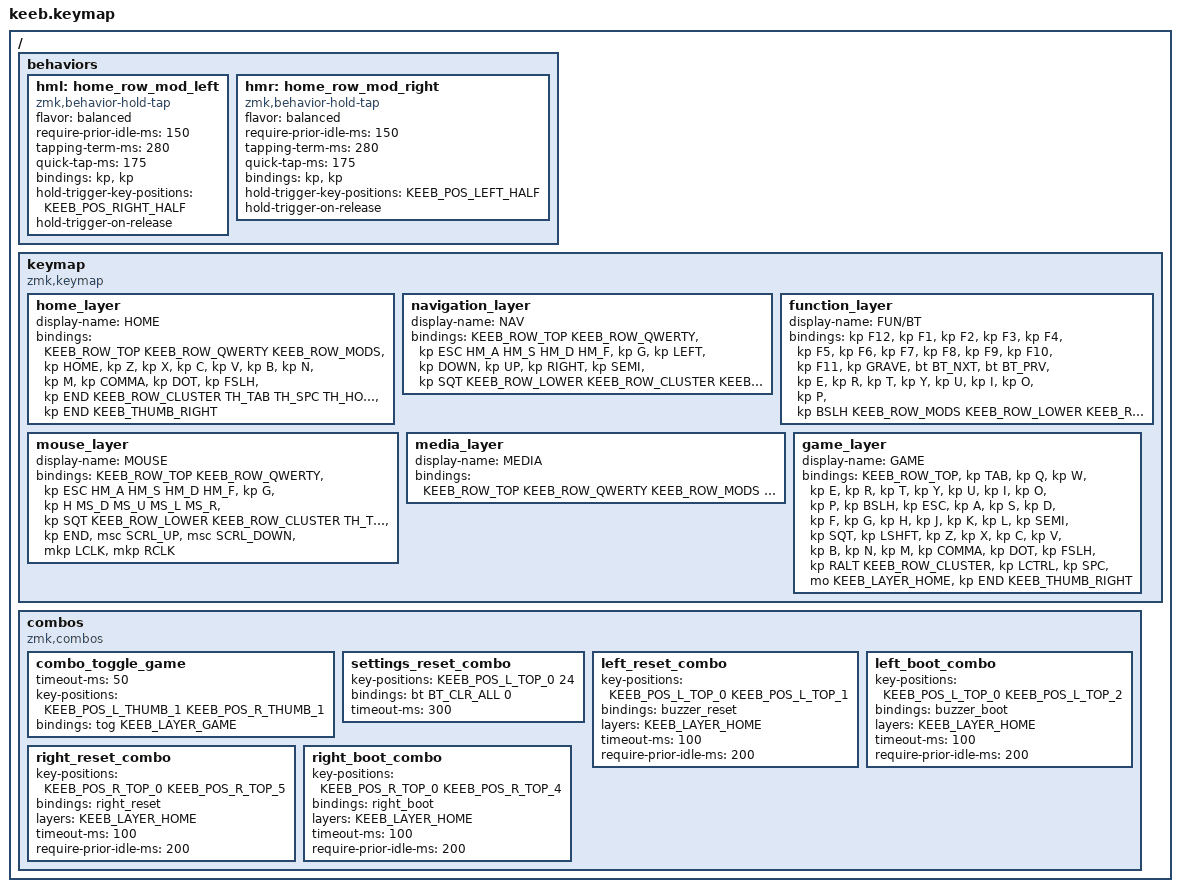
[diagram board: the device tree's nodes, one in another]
/*
 * keeb keymap - bring-up build.
 *
 * HOME is a full 12-column grid (6 left PLUS 6 right, split marked by the wider
 * gap): 4 alpha rows, a 4-key extra row (LBKT/RBKT on the left half,
 * BSLH/RBRC on the right), and an 8-key thumb row = 60 positions (0..59).
 * The other four layers are placeholders "for now": they duplicate the HOME
 * grid so every position is mapped while the matrix is brought up.
 *
 * The zmk,matrix-transform in keeb.dtsi maps these 60 positions onto the
 * physical 6x6 matrix (rows 0-3 alpha; row 4 = the 2 extra keys per half
 * at local cols 2-3; row 5 = thumb cluster, first 4 cols per half), so
 * this grid stays visually clean regardless of wiring.
 * Replace the placeholder layers with real per-layer content as needed.
 *
 * NOTE: a layer behavior (&mo / &to / &lt / &tog) takes a layer *index*, not a
 * key name. `&mo HOME` compiles happily, passes the HOME keycode (0x07004a) as
 * the layer id, and the key silently does nothing - which is what these bindings
 * used to be. Every layer reference below therefore goes through the
 * KEEB_LAYER_* constants in keeb-positions.dtsi, and app/scripts/gen-contract.mjs
 * fails the build when a layer argument in this file is out of range or is a
 * name instead of an index.
 *
 * Reachable today: NAV, FUN and MOUSE from the HOME/MOUSE thumb hold-taps
 * (TH_TAB / TH_SPC / TH_HOME), HOME as &mo KEEB_LAYER_HOME from every other
 * layer, GAME from the thumb combo (&tog KEEB_LAYER_GAME). MEDIA is defined but
 * not yet reachable.
 *
 * Layer names double as the artwork lookup order for tools/gen_art.py.
 */

#include <behaviors.dtsi>
#include <dt-bindings/zmk/keys.h>
#include <dt-bindings/zmk/bt.h>
#include <dt-bindings/zmk/pointing.h>

/* Key positions and layer indices: keeb-module/dts/keeb-positions.dtsi. Never
 * name a position or a layer with a bare number in this file. */
#include <keeb-positions.dtsi>

// Home-row mods: left hand A S D F, right hand J K L ; — each row outward from the split.
// Each hand uses ITS OWN hold-tap, because the two differ in exactly one
// property: which positions may trigger the hold (the opposite half).
#define HM_A &hml LGUI A
#define HM_S &hml LALT S
#define HM_D &hml LCTRL D
#define HM_F &hml LSHFT F

#define HM_SM &hmr RGUI SEMI
#define HM_L &hmr RALT L
#define HM_K &hmr RCTRL K
#define HM_J &hmr RSHFT J

// Thumb hold-momentary layers
#define TH_TAB &lt KEEB_LAYER_NAV TAB
#define TH_SPC &lt KEEB_LAYER_FUN SPC
#define TH_HOME &lt KEEB_LAYER_MOUSE HOME

// Mouse-layer pointer keys (MOUSE layer, right home row)
#define MS_D &mmv MOVE_DOWN
#define MS_U &mmv MOVE_UP
#define MS_R &mmv MOVE_RIGHT
#define MS_L &mmv MOVE_LEFT

/* The six shared rows, drawn once. Row order is the matrix order (rows 0-5 of
 * keeb.dtsi's transform): left half cols 0-5, right half cols 6-11, the right
 * half drawn outward from the gap.
 *
 *   KEEB_ROW_TOP       row 0   number row
 *   KEEB_ROW_QWERTY    row 1   Q-P
 *   KEEB_ROW_MODS      row 2   home row, home-row mods included
 *   KEEB_ROW_LOWER     row 3   Z-/   (HOME keeps its own variant of this row)
 *   KEEB_ROW_CLUSTER   row 4   the four inner-cluster keys
 *   KEEB_THUMB_BACK    row 5   left thumb, TAB / SPC / back to HOME
 *   KEEB_THUMB_RIGHT   row 5   right thumb, PG_UP PG_DN BSPC ENTER
 *
 * A layer below names the rows it shares and spells out only the rows it
 * changes — which is all a layer ever is: HOME plus a few cells. */
#define KEEB_ROW_TOP     &kp EQUAL  &kp N1   &kp N2   &kp N3   &kp N4   &kp N5      &kp N6   &kp N7   &kp N8   &kp N9   &kp N0   &kp MINUS
#define KEEB_ROW_QWERTY  &kp GRAVE  &kp Q    &kp W    &kp E    &kp R    &kp T       &kp Y    &kp U    &kp I    &kp O    &kp P    &kp BSLH
#define KEEB_ROW_MODS    &kp ESC    HM_A     HM_S     HM_D     HM_F     &kp G       &kp H    HM_J     HM_K     HM_L     HM_SM    &kp SQT
#define KEEB_ROW_LOWER   &kp LCTRL  &kp Z    &kp X    &kp C    &kp V    &kp B       &kp N    &kp M    &kp COMMA &kp DOT &kp FSLH &kp RALT
#define KEEB_ROW_CLUSTER &kp LBKT   &kp RBKT                                                              &kp BSLH  &kp RBRC

#define KEEB_THUMB_BACK  &kp TAB    &kp SPC  &mo KEEB_LAYER_HOME &kp END
#define KEEB_THUMB_RIGHT &kp PG_UP  &kp PG_DN &kp BSPC &kp ENTER

/ {
	/* Timeless home-row mods (recommended config from this ZMK version's
	 * hold-tap docs), as a mirrored pair.
	 *   balanced flavor + hold-trigger-on-release + positional hold
	 *   (opposite-hand keys) -> same-hand letter rolls never false-hold,
	 *   cross-hand mods resolve reliably regardless of timing.
	 *   require-prior-idle-ms 150 -> fast typing resolves as tap instantly.
	 *   tapping-term-ms 280 -> intentional same-hand holds still work.
	 *   quick-tap-ms 175 -> tapped key can be held for repeat.
	 *
	 * hml is bound by the LEFT home row and triggered by the RIGHT half; hmr is
	 * its mirror, built from the same two named lists in keeb-positions.dtsi so
	 * the pair cannot drift apart. Both were wired to &hml before, which left
	 * the right hand's mods triggerable only from its own half - the false-hold
	 * case positional triggering exists to remove - and &hmr compiled with no
	 * bindings at all. The generator now fails if a declared behavior node has
	 * no binding, or if either trigger list is not exactly one half. */
	behaviors {
		hml: home_row_mod_left {
			compatible = "zmk,behavior-hold-tap";
			#binding-cells = <2>;
			flavor = "balanced";
			require-prior-idle-ms = <150>;
			tapping-term-ms = <280>;
			quick-tap-ms = <175>;
			bindings = <&kp>, <&kp>;
			/* The OTHER half. A home-row mod resolves as a hold when the
			 * opposite hand plays a key, and never from its own hand's letters. */
			hold-trigger-key-positions = <KEEB_POS_RIGHT_HALF>;
			hold-trigger-on-release;
		};
		hmr: home_row_mod_right {
			compatible = "zmk,behavior-hold-tap";
			#binding-cells = <2>;
			flavor = "balanced";
			require-prior-idle-ms = <150>;
			tapping-term-ms = <280>;
			quick-tap-ms = <175>;
			bindings = <&kp>, <&kp>;
			/* Mirror of hml: same properties, the other half's positions. */
			hold-trigger-key-positions = <KEEB_POS_LEFT_HALF>;
			hold-trigger-on-release;
		};
	};

keymap {
    compatible = "zmk,keymap";

    home_layer {
        display-name = "HOME";
        bindings = <
            KEEB_ROW_TOP
            KEEB_ROW_QWERTY
            KEEB_ROW_MODS
            &kp HOME  &kp Z   &kp X   &kp C   &kp V   &kp B          &kp N    &kp M    &kp COMMA &kp DOT &kp FSLH &kp END
            KEEB_ROW_CLUSTER
            TH_TAB  TH_SPC  TH_HOME  &kp END   KEEB_THUMB_RIGHT
        >;
    };

    navigation_layer {
        display-name = "NAV";
        /* Row 2 becomes the arrow cluster under the right hand; the left
         * thumb returns to HOME instead of momentary-shifting. */
        bindings = <
            KEEB_ROW_TOP
            KEEB_ROW_QWERTY
            &kp ESC   HM_A    HM_S    HM_D    HM_F    &kp G          &kp LEFT &kp DOWN &kp UP   &kp RIGHT &kp SEMI &kp SQT
            KEEB_ROW_LOWER
            KEEB_ROW_CLUSTER
            KEEB_THUMB_BACK  KEEB_THUMB_RIGHT
        >;
    };

    function_layer {
        display-name = "FUN/BT";
        /* Row 0 is F1-F12 (F12 first: it is the outer key of the row and the
         * one you reach with the pinky next to the corner). Row 1's two inner
         * keys switch BLE hosts. */
        bindings = <
            &kp F12   &kp F1  &kp F2  &kp F3  &kp F4  &kp F5         &kp F6   &kp F7   &kp F8   &kp F9   &kp F10  &kp F11
            &kp GRAVE &bt BT_NXT &bt BT_PRV &kp E &kp R &kp T        &kp Y    &kp U    &kp I    &kp O    &kp P    &kp BSLH
            KEEB_ROW_MODS
            KEEB_ROW_LOWER
            KEEB_ROW_CLUSTER
            KEEB_THUMB_BACK  KEEB_THUMB_RIGHT
        >;
    };

    mouse_layer {
        display-name = "MOUSE";
        /* The right home row is the pointer: J/K/L/; become down/up/left/right
         * and the right thumb becomes scroll + clicks. The left thumb keeps
         * its momentary layers so NAV and FUN stay reachable from MOUSE. */
        bindings = <
            KEEB_ROW_TOP
            KEEB_ROW_QWERTY
            &kp ESC   HM_A    HM_S    HM_D    HM_F    &kp G          &kp H    MS_D     MS_U     MS_L     MS_R     &kp SQT
            KEEB_ROW_LOWER
            KEEB_ROW_CLUSTER
            TH_TAB  TH_SPC  TH_HOME  &kp END   &msc SCRL_UP &msc SCRL_DOWN &mkp LCLK &mkp RCLK
        >;
    };

    media_layer {
        display-name = "MEDIA";
        /* Placeholder: identical to HOME apart from the outer keys of row 3,
         * so the layer is fully mapped while MEDIA is still unreachable.
         * Reachable only through a &mo/&to/&tog binding added on the HOME row
         * or from the configurator. */
        bindings = <
            KEEB_ROW_TOP
            KEEB_ROW_QWERTY
            KEEB_ROW_MODS
            KEEB_ROW_LOWER
            KEEB_ROW_CLUSTER
            KEEB_THUMB_BACK  KEEB_THUMB_RIGHT
        >;
    };

    game_layer {
        display-name = "GAME";
        /* Plain keys instead of home-row hold-taps: a game wants modifiers held
         * on their own keys, not a mod that has to survive a roll. TAB sits on
         * GRAVE, where the left pinky already is, and the left pinky's outer
         * row-3 key is a real LSHIFT instead of LCTRL. */
        bindings = <
            KEEB_ROW_TOP
            &kp TAB   &kp Q   &kp W   &kp E   &kp R   &kp T          &kp Y    &kp U    &kp I    &kp O    &kp P    &kp BSLH
            &kp ESC   &kp A   &kp S   &kp D   &kp F   &kp G          &kp H    &kp J    &kp K    &kp L    &kp SEMI &kp SQT
            &kp LSHFT &kp Z   &kp X   &kp C   &kp V   &kp B          &kp N    &kp M    &kp COMMA &kp DOT &kp FSLH &kp RALT
            KEEB_ROW_CLUSTER
            &kp LCTRL &kp SPC &mo KEEB_LAYER_HOME &kp END  KEEB_THUMB_RIGHT
        >;
    };
};

	/* Hold both outer top corners (KEEB_POS_L_TOP_0 + KEEB_POS_R_TOP_0, i.e.
	 * EQUAL + MINUS in HOME today) to clear ALL BLE host bonds/profiles
	 * (zmk_ble_clear_all_bonds()). Afterwards the keyboard advertises unpaired;
	 * pair the host fresh.
	 * NB: this clears HOST bonds, NOT the split-central/peripheral bond;
	 * power-cycle both halves if the split bond itself needs redoing.
	 * (This ZMK version has no &settings_reset behavior.) */
	combos {
		compatible = "zmk,combos";

		combo_toggle_game {
			timeout-ms = <50>;
			/* The same thumb slot on each hand - mirror-symmetric by name.
			 * GAME is the layer the buzzer announces (beep-layers in
			 * keeb_left.overlay): two rising notes on the way in, the same two
			 * upside down on the way out, so the layer you are in is audible
			 * without looking. That is a property of the buzzer node, not of this
			 * combo - any other way of toggling GAME sounds the same. */
			key-positions = <KEEB_POS_L_THUMB_1 KEEB_POS_R_THUMB_1>;
			bindings = <&tog KEEB_LAYER_GAME>;
		};

		/* Host bond clear: the left corner + the left ESC. Both keys live on
		 * the LEFT half, and a combo only triggers on the half where both of
		 * its keys live. */
		settings_reset_combo {
			key-positions = <KEEB_POS_L_TOP_0 24 /* 24 = &kp ESC, left home row */>;
			bindings = <&bt BT_CLR_ALL 0>;
			timeout-ms = <300>;
		};

		/* Reboot / UF2-bootloader chords, HOME layer only.
		 *   LEFT:  the corner plus the next slots toward the split:
		 *          + L_TOP_1 = reset, + L_TOP_2 = bootloader. Combos are
		 *          evaluated on the central half and &sys_reset / &bootloader
		 *          are source-local, so these reboot the LEFT half directly.
		 *          The reset chord sounds first (buzzer on P1.01, see
		 *          buzzer_reset in keeb.dtsi) with a random pattern, and the
		 *          bootloader chord sounds the `bootloader` tune (buzzer_boot,
		 *          three descending notes) - different sounds, because mixing up
		 *          "reboot" and "reboot into the UF2 bootloader" is how people
		 *          conclude the keyboard is bricked.
		 *   RIGHT: the corner plus its two inner neighbours (R_TOP_5 / R_TOP_4,
		 *          since the right half counts outward-in): = reset,
		 *          bootloader, via keeb,remote-reset which forwards the reboot
		 *          to the right half over the split behavior transport (a direct
		 *          &sys_reset binding would reboot the LEFT half here - the combo
		 *          fires centrally even though its keys live on the right).
		 * require-prior-idle-ms keeps fast typing ("=1", "=2", "-7", dates,
		 * formulas) from tripping the chords: they only arm after ~200 ms
		 * without any other keypress. */
		left_reset_combo {
			key-positions = <KEEB_POS_L_TOP_0 KEEB_POS_L_TOP_1>;
			/* &buzzer_reset (keeb.dtsi) = zmk,behavior-buzzer: a random beep
			 * pattern on the left half's buzzer (P1.01), then &sys_reset when the
			 * tone ends. &sys_reset alone reboots inside its own callback, i.e.
			 * before anything could sound, and a combo only carries one binding -
			 * so the tone and the reboot have to live in the same behavior.
			 * The right half has no buzzer: its mirror chords use &right_reset and
			 * stay silent. */
			bindings = <&buzzer_reset>;
			layers = <KEEB_LAYER_HOME>;
			timeout-ms = <100>;
			require-prior-idle-ms = <200>;
		};

		left_boot_combo {
			key-positions = <KEEB_POS_L_TOP_0 KEEB_POS_L_TOP_2>;
			/* &buzzer_boot (keeb.dtsi): the `bootloader` tune, then &bootloader.
			 * Same one-behavior constraint as the reset chord above - &bootloader
			 * reboots inside its own callback, so nothing else in the combo could
			 * ever sound. The UF2 drive shows up about 0.3 s after the chord, which
			 * is the price of hearing which chord you hit. */
			bindings = <&buzzer_boot>;
			layers = <KEEB_LAYER_HOME>;
			timeout-ms = <100>;
			require-prior-idle-ms = <200>;
		};

		/* Mirror of the left pair: KEEB_POS_R_TOP_0 is the right corner. */
		right_reset_combo {
			key-positions = <KEEB_POS_R_TOP_0 KEEB_POS_R_TOP_5>;
			bindings = <&right_reset>;
			layers = <KEEB_LAYER_HOME>;
			timeout-ms = <100>;
			require-prior-idle-ms = <200>;
		};

		right_boot_combo {
			key-positions = <KEEB_POS_R_TOP_0 KEEB_POS_R_TOP_4>;
			bindings = <&right_boot>;
			layers = <KEEB_LAYER_HOME>;
			timeout-ms = <100>;
			require-prior-idle-ms = <200>;
		};
	};
};
